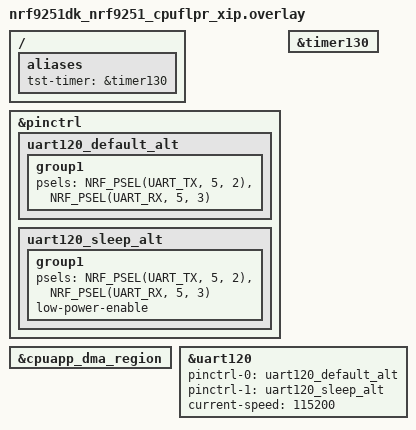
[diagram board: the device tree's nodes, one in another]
/*
 * Copyright (c) 2025 Nordic Semiconductor ASA
 *
 * SPDX-License-Identifier: LicenseRef-Nordic-5-Clause
 */

/ {
	aliases {
		tst-timer = &timer130;
	};
};

/* UART device used for test
 * not the default UART assignment for the LD
 */
&pinctrl {
	uart120_default_alt: uart120_default_alt {
		group1 {
			psels = <NRF_PSEL(UART_TX, 5, 2)>,
				<NRF_PSEL(UART_RX, 5, 3)>;
		};
	};

	uart120_sleep_alt: uart120_sleep_alt {
		group1 {
			psels = <NRF_PSEL(UART_TX, 5, 2)>,
				<NRF_PSEL(UART_RX, 5, 3)>;
			low-power-enable;
		};
	};
};

&timer130 {
	status = "okay";
};

&cpuapp_dma_region {
	status = "okay";
};

dut: &uart120 {
	status = "okay";
	pinctrl-0 = <&uart120_default_alt>;
	pinctrl-1 = <&uart120_sleep_alt>;
	pinctrl-names = "default", "sleep";
	current-speed = <115200>;
	/delete-property/ hw-flow-control;
};
